# M251_v1 register map
File version: 1.0
Registers are 32-bit, read-write, reset 0x0 unless marked. A register's access mark holds for its fields unless they carry their own. Offsets are from the block's base; [hi:lo] are bit positions; {n}, {i} and the like mark numbered series; 'fields as' and 'values as' point back to an identical list.

## EADC — EADC Register Map
Base 0x40043000
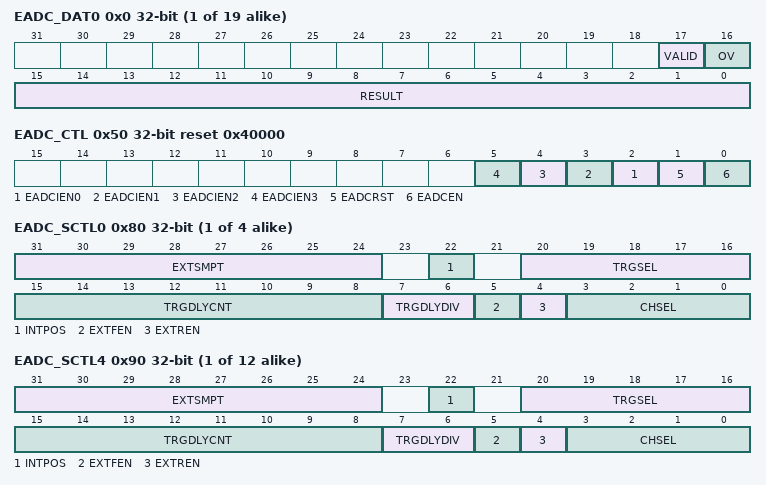
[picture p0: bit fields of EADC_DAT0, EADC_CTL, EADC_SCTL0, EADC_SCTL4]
{0x0+4i} EADC_DAT{i} ro (i=0..18) — ADC Data Register {i} for Sample Module {i}
  [17] VALID — Valid Flag. This bit is set to 1 when corresponding sample module channel analog input conversion is completed and cleared by hardware after EADC_DAT register is read.
    0=Data in RESULT[11:0] bits is not valid; 1=Data in RESULT[11:0] bits is valid
  [16] OV — Overrun Flag. If converted data in RESULT[11:0] has not been read before new conversion result is loaded to this register, OV is set to 1. Note: It is cleared by hardware after EADC_DAT register is read.
    0=Data in RESULT[11:0] is recent conversion result; 1=Data in RESULT[11:0] is overwrite
  [15:0] RESULT — ADC Conversion Result. This field contains 12 bits conversion result.
0x4C EADC_CURDAT ro — EADC PDMA Current Transfer Data Register
  [18:0] CURDAT — EADC PDMA Current Transfer Data (Read Only). Note: After PDMA reads this register, the VAILD of the shadow EADC_DAT register will be automatically cleared.
0x50 EADC_CTL reset 0x40000 — ADC Control Register
  [n+2] EADCIEN{n} (n=0..3) — Specific Sample Module ADC ADINT{n} Interrupt Enable Bit. The ADC converter generates a conversion end ADIF{n} (EADC_STATUS2[{n}]) upon the end of specific sample module ADC conversion. If EADCIEN{n} bit is set then conversion end interrupt request ADINT{n} is generated.
    0=Specific sample module ADC ADINT{n} interrupt function Disabled; 1=Specific sample module ADC ADINT{n} interrupt function Enabled
  [1] EADCRST — EADC ADC Converter Control Circuits Reset. Note: EADCRST bit remains 1 during EADC reset. When EADC reset end, the EADCRST bit is automatically cleared to 0.
    0=No effect; 1=Cause EADC control circuits reset to initial state, but not change the EADC registers value
  [0] EADCEN — ADC Converter Enable Bit. Note: Before starting ADC conversion function, this bit should be set to 1. Clear it to 0 to disable ADC converter analog circuit power consumption.
    0=Disabled EADC; 1=Enabled EADC
0x54 EADC_SWTRG wo — ADC Sample Module Software Start Register
  [18:0] SWTRG — ADC Sample Module 0~18 Software Force to Start EADC Conversion. Note: After writing this register to start EADC conversion, the EADC_PENDSTS register will show which sample module will conversion. If user want to disable the conversion of the sample module, user can write EADC_PENDSTS register to clear it.
    0=No effect; 1=Cause an EADC conversion when the priority is given to sample module
0x58 EADC_PENDSTS — ADC Start of Conversion Pending Flag Register
  [18:0] STPF — ADC Sample Module 0~18 Start of Conversion Pending Flag. Read Operation:
    0=There is no pending conversion for sample module; 1=Sample module EADC start of conversion is pending. Clear pending flag and stop conversion for corresponding sample module
0x5C EADC_OVSTS — ADC Sample Module Start of Conversion Overrun Flag Register
  [18:0] SPOVF — ADC SAMPLE0~18 Overrun Flag. Note: This bit is cleared by writing 1 to it.
    0=No sample module event overrun; 1=Indicates a new sample module event is generated while an old one event is pending
{0x80+4i} EADC_SCTL{i} (i=0..3) — ADC Sample Module {i} Control Register
  [31:24] EXTSMPT — EADC Sampling Time Extend. When ADC converting at high conversion rate, the sampling time of analog input voltage may not enough if input channel loading is heavy, user can extend ADC sampling time after trigger source is coming to get enough sampling time. EXTSMPT can be set from 0~8'd251.
  [22] INTPOS — Interrupt Flag Position Select
    0=Set ADIFn (EADC_STATUS2[n], n=0~3) at ADC end of conversion; 1=Set ADIFn (EADC_STATUS2[n], n=0~3) at ADC start of conversion
  [20:16] TRGSEL — ADC Sample Module Start of Conversion Trigger Source Selection
  [15:8] TRGDLYCNT — ADC Sample Module Start of Conversion Trigger Delay Time. Note: If TRGDLYCNT is set to 1, trigger delay time is actullay the same as TRGDLYCNT is set to 2 for hardware operation.
  [7:6] TRGDLYDIV — ADC Sample Module Start of Conversion Trigger Delay Clock Divider Selection. Trigger delay clock frequency:
    0=EADC_CLK/1; 1=EADC_CLK/2; 2=EADC_CLK/4; 3=EADC_CLK/16
  [5] EXTFEN — ADC External Trigger Falling Edge Enable Bit
    0=Falling edge Disabled when ADC selects EADC0_ST as trigger source; 1=Falling edge Enabled when ADC selects EADC0_ST as trigger source
  [4] EXTREN — ADC External Trigger Rising Edge Enable Bit
    0=Rising edge Disabled when ADC selects EADC0_ST as trigger source; 1=Rising edge Enabled when ADC selects EADC0_ST as trigger source
  [3:0] CHSEL — ADC Sample Module Channel Selection. Note: When internal EADC channel16, 17 or 18 is selected, EADC_CH15 is useless.
{0x80+4i} EADC_SCTL{i} (i=4..15) — ADC Sample Module {i} Control Register
  [31:24] EXTSMPT — EADC Sampling Time Extend. When ADC converting at high conversion rate, the sampling time of analog input voltage may not enough if input channel loading is heavy, SW can extend ADC sampling time after trigger source is coming to get enough sampling time.EXTSMPT can be set from 0~8'd251.
  [22] INTPOS — Interrupt Flag Position Select
    values as EADC_SCTL0.INTPOS
  [20:16] TRGSEL — ADC Sample Module Start of Conversion Trigger Source Selection
  [15:8] TRGDLYCNT — ADC Sample Module Start of Conversion Trigger Delay Time. Note: If TRGDLYCNT is set to 1, Trigger delay time is actullay the same as TRGDLYCNT is set to 2 for hardware operation.
  [7:6] TRGDLYDIV — ADC Sample Module Start of Conversion Trigger Delay Clock Divider Selection. Trigger delay clock frequency:
    0=EADC_CLK/1; 1=EADC_CLK/2; 2=EADC_CLK/4; 3=EADC_CLK/16
  [5] EXTFEN — ADC External Trigger Falling Edge Enable Bit
    values as EADC_SCTL0.EXTFEN
  [4] EXTREN — ADC External Trigger Rising Edge Enable Bit
    values as EADC_SCTL0.EXTREN
  [3:0] CHSEL — ADC Sample Module Channel Selection. Note: when internal EADC channel16, 17 or 18 is selected, EADC_CH15 is useless.
{0x80+4i} EADC_SCTL{i} (i=16..18) — ADC Sample Module {i} Control Register
  [31:24] EXTSMPT — EADC Sampling Time Extend. When ADC converting at high conversion rate, the sampling time of analog input voltage may not enough if input channel loading is heavy, SW can extend ADC sampling time after trigger source is coming to get enough sampling time. EXTSMPT can be set from 0~8'd255. The range of start delay time is from 0~255 EADC clock.
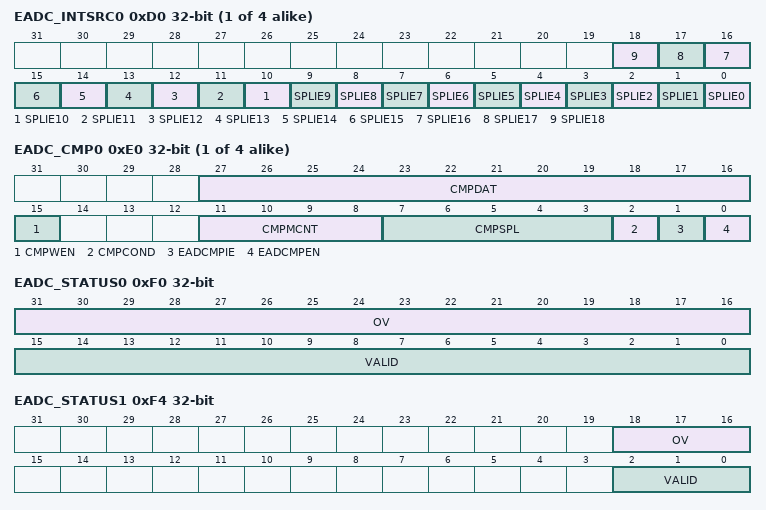
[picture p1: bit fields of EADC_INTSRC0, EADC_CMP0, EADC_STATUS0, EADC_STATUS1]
{0xD0+4i} EADC_INTSRC{i} (i=0..3) — EADC Interrupt {i} Source Enable Control Register.
  [n] SPLIE{n} (n=0..18) — Sample Module {n} Interrupt Enable Bit
    0=Sample Module {n} interrupt Disabled; 1=Sample Module {n} interrupt Enabled
{0xE0+4i} EADC_CMP{i} (i=0..3) — ADC Result Compare Register {i}
  [27:16] CMPDAT — Comparison Data. The 12 bits data is used to compare with conversion result of specified sample module. User can use it to monitor the external analog input pin voltage transition without imposing a load on software.
  [15] CMPWEN — Compare Window Mode Enable Bit. Note: This bit is only present in EADC_CMP0 and EADC_CMP2 register.
    0=EADCMPF0 (EADC_STATUS2[4]) will be set when EADC_CMP0 compared condition matched. EADCMPF2 (EADC_STATUS2[6]) will be set when EADC_CMP2 compared condition matched; 1=EADCMPF0 (EADC_STATUS2[4]) will be set when both EADC_CMP0 and EADC_CMP1 compared condition matched. EADCMPF2 (EADC_STATUS2[6]) will be set when both EADC_CMP2 and EADC_CMP3 compared condition matched
  [11:8] CMPMCNT — Compare Match Count
  [7:3] CMPSPL — Compare Sample Module Selection
    {v}=Sample Module {v} conversion result EADC_DAT{v} is selected to be compared (v=0..18)
  [2] CMPCOND — Compare Condition
    0=Set the compare condition as that when a 12-bit ADC conversion result is less than the 12-bit CMPDAT (EADC_CMPn [27:16]), the internal match counter will increase one; 1=Set the compare condition as that when a 12-bit ADC conversion result is greater or equal to the 12-bit CMPDAT (EADC_CMPn [27:16]), the internal match counter will increase one
  [1] EADCMPIE — ADC Result Compare Interrupt Enable Bit
    0=Compare function interrupt Disabled; 1=Compare function interrupt Enabled
  [0] EADCMPEN — ADC Result Compare Enable Bit
    0=Compare Disabled; 1=Compare Enabled
0xF0 EADC_STATUS0 ro — ADC Status Register 0
  [31:16] OV — EADC_DAT0~15 Overrun Flag
  [15:0] VALID — EADC_DAT0~15 Data Valid Flag
0xF4 EADC_STATUS1 ro — ADC Status Register 1
  [18:16] OV — EADC_DAT16~18 Overrun Flag
  [2:0] VALID — EADC_DAT16~18 Data Valid Flag
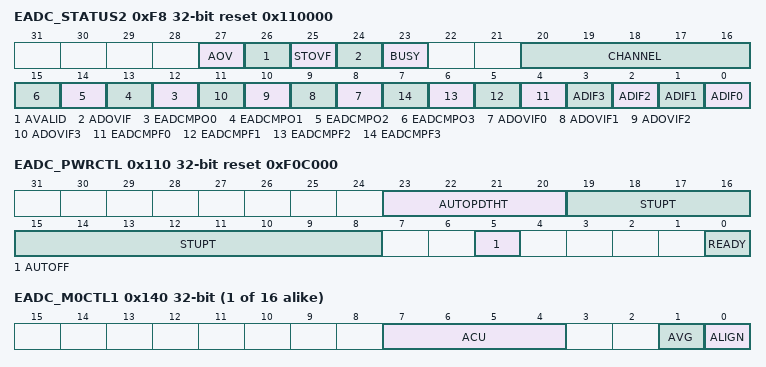
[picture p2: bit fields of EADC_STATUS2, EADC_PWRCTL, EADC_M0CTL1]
0xF8 EADC_STATUS2 reset 0x110000 — ADC Status Register 2
  [27] AOV — All Sample Module ADC Result Data Register Overrun Flags Check. Note: This bit will keep 1 when any OVn Flag is equal to 1.
    0=None of sample module data register overrun flag OVn (EADC_DATn[16]) is set to 1; 1=Any one of sample module data register overrun flag OVn (EADC_DATn[16]) is set to 1
  [26] AVALID — All Sample Module ADC Result Data Register EADC_DAT Data Valid Flag Check. Note: This bit will keep 1 when any VALIDn Flag is equal to 1.
    0=None of sample module data register valid flag VALIDn (EADC_DATn[17]) is set to 1; 1=Any one of sample module data register valid flag VALIDn (EADC_DATn[17]) is set to 1
  [25] STOVF — All ADC Sample Module Start of Conversion Overrun Flags Check. Note: This bit will keep 1 when any SPOVFn Flag is equal to 1.
    0=None of sample module event overrun flag SPOVFn (EADC_OVSTS[n]) is set to 1; 1=Any one of sample module event overrun flag SPOVFn (EADC_OVSTS[n]) is set to 1
  [24] ADOVIF — All ADC Interrupt Flag Overrun Bits Check. Note: This bit will keep 1 when any ADOVIFn Flag is equal to 1.
    0=None of ADINT interrupt flag ADOVIFn (EADC_STATUS2[11:8]) is overwritten to 1; 1=Any one of ADINT interrupt flag ADOVIFn (EADC_STATUS2[11:8]) is overwritten to 1
  [23] BUSY ro — ADC Conveter Busy/Idle Status (Read Only). Note: Once a trigger source is coming, this bit must wait 2 EADC_CLK synchronization then the BUSY status will be high. The status will be high to low when the current conversion is finished.
    0=EADC is in idle state; 1=EADC is busy for sample or conversion
  [20:16] CHANNEL ro — Current Conversion Channel (Read Only)
  [n+12] EADCMPO{n} (n=0..3) — EADC Compare {n} Output Status. The 12 bits compare{n} data CMPDAT{n} (EADC_CMP{n}[27:16]) is used to compare with conversion result of specified sample module. User can use it to monitor the external analog input pin voltage status.
    0=Conversion result in EADC_DAT is less than CMPDAT{n} setting; 1=Conversion result in EADC_DAT is greater than or equal to CMPDAT{n} setting
  [n+8] ADOVIF{n} (n=0..3) — ADC ADINT{n} Interrupt Flag Overrun. Note: This bit is cleared by writing 1 to it.
    0=ADINT{n} interrupt flag is not overwritten to 1; 1=ADINT{n} interrupt flag is overwritten to 1
  [n+4] EADCMPF{n} (n=0..3) — EADC Compare {n} Flag. When the specific sample module ADC conversion result meets setting condition in EADC_CMP{n} then this bit is set to 1. Note: This bit is cleared by writing 1 to it.
    0=Conversion result in EADC_DAT does not meet EADC_CMP{n} register setting; 1=Conversion result in EADC_DAT meets EADC_CMP{n} register setting
  [n] ADIF{n} (n=0..3) — ADC ADINT{n} Interrupt Flag. Note1: This bit is cleared by writing 1 to it. Note2:This bit indicates whether an ADC conversion of specific sample module has been completed
    0=No ADINT{n} interrupt pulse received; 1=ADINT{n} interrupt pulse has been received
0xFC EADC_STATUS3 ro reset 0x1F — ADC Status Register 3
  [4:0] CURSPL — EADC Current Sample Module (Read Only). This register shows the current EADC is controlled by which sample module control logic modules. If the EADC is Idle, the bit filed will be set to 0x1F.
0x110 EADC_PWRCTL reset 0xF0C000 — EADC Power Management Control Register
  [23:20] AUTOPDTHT — Auto Power Down Threshold Time
    7=8 EADC clock for power down threshold time; 8=16 EADC clock for power down threshold time; 9=32 EADC clock for power down threshold time; 10=64 EADC clock for power down threshold time; 11=128 EADC clock for power down threshold time; 12=256 EADC clock for power down threshold time
  [19:8] STUPT — EADC Start-up Time. Set this bit fields to adjust start-up time. The minimum start-up time of EADC is 10us.
  [5] AUTOFF — Auto Off Mode
    0=Auto off function Disabled; 1=Auto off function Enabled. When AUTOFF is set to 1, EADC will be powered off automatically to save power
  [0] READY ro — EADC Start-up Completely and Ready for Conversion (Read Only)
    0=Power-on sequence is still in progress; 1=EADC is ready for conversion
0x130 EADC_PDMACTL — ADC PDMA Control Register
  [18:0] PDMATEN — PDMA Transfer Enable Bit. When EADC conversion is completed, the converted data is loaded into EADC_DATn (n: 0 ~ 18) register, user can enable this bit to generate a PDMA data transfer request.
    0=PDMA data transfer Disabled; 1=PDMA data transfer Enabled
{0x140+4i} EADC_M{i}CTL1 (i=0..15) — ADC Sample Module{i} Control Register 1
  [7:4] ACU — Number of Accumulated Conversion Results Selection
    0=1 conversion result will be accumulated; 1=2 conversion result will be accumulated; 2=4 conversion result will be accumulated; 3=8 conversion result will be accumulated; 4=16 conversion result will be accumulated; 5=32 conversion result will be accumulated; 6=64 conversion result will be accumulated; 7=128 conversion result will be accumulated; 8=256 conversion result will be accumulated
  [1] AVG — Average Mode Selection
    0=Conversion results will be stored in data register without averaging; 1=Conversion results in data register will be averaged
  [0] ALIGN — Alignment Selection
    0=The conversion result will be right aligned in data register; 1=The conversion result will be left aligned in data register
0x208 EADC_OFFSETCAL reset 0x1F — ADC Result Offset Cancellation Register
  [4:0] OFFSETCANCEL — ADC Offset Cancellation Trim Bits. When CALEN(EADC_CTL[8]) is set to 1, the offset cancellation trim bits will compensate ADC result offset. When this bit is set to 0, the offset cancellation trim bits have no effect to ADC result. Note1:These 5 bits trim value wouln't latched into EADC_OFFSETCAL automatically when Flash initalization. User must read DCR2 by ISP command first, then write the value to OFFSETCANCEL. Note2: OFFSETCANCEL is signed format. OFFSETCANCEL will sign extension to 12 bit by hardware to perform signed addition with EADC conversion result if CALEN is enabled.
